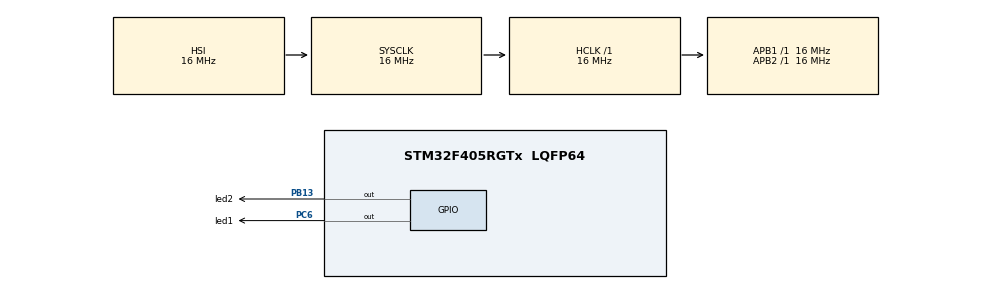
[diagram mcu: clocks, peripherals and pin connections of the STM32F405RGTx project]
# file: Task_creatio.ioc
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Mcu.Family=STM32F4
Mcu.Name=STM32F405RGTx
Mcu.Package=LQFP64
NVIC.PriorityGroup=NVIC_PRIORITYGROUP_4
PB13.GPIO_Label=led2
PB13.Signal=GPIO_Output
PC6.GPIO_Label=led1
PC6.Signal=GPIO_Output
ProjectManager.HeapSize=0x200
ProjectManager.StackSize=0x400
ProjectManager.TargetToolchain=STM32CubeIDE
RCC.AHBFreq_Value=16000000
RCC.APB1Freq_Value=16000000
RCC.APB2Freq_Value=16000000
RCC.CortexFreq_Value=16000000
RCC.HSE_VALUE=25000000
RCC.HSI_VALUE=16000000
RCC.LSE_VALUE=32768
RCC.SYSCLKFreq_VALUE=16000000
RCC.VCOOutputFreq_Value=192000000
board=custom

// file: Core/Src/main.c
/* USER CODE BEGIN Header */
/**
  ******************************************************************************
  * @file           : main.c
  * @brief          : Main program body
  ******************************************************************************
  * @attention
  *
  * Copyright (c) 2025 STMicroelectronics.
  * All rights reserved.
  *
  * This software is licensed under terms that can be found in the LICENSE file
  * in the root directory of this software component.
  * If no LICENSE file comes with this software, it is provided AS-IS.
  *
  ******************************************************************************
  */
/* USER CODE END Header */
#include "main.h"

/* USER CODE BEGIN Includes */
#include "FreeRTOS.h"
#include "task.h"

/* USER CODE END Includes */

void SystemClock_Config(void);
static void MX_GPIO_Init(void);
/* USER CODE BEGIN PFP */
static void myTask1(void *parameter);
static void myTask2(void *parameter);
/* USER CODE END PFP */

int main(void)
{
  /* USER CODE BEGIN 1 */
	TaskHandle_t myTask1Handle;
	TaskHandle_t myTask2Handle;
  /* USER CODE END 1 */

  /* MCU Configuration--------------------------------------------------------*/

  /* Reset of all peripherals, Initializes the Flash interface and the Systick. */
  HAL_Init();

  /* Configure the system clock */
  SystemClock_Config();

  /* Initialize all configured peripherals */
  MX_GPIO_Init();
  /* USER CODE BEGIN 2 */
  xTaskCreate(myTask1, "LED1", 128, NULL, 1, &myTask1Handle);
  xTaskCreate(myTask2, "LED2", 128, NULL, 2, &myTask2Handle);
  vTaskStartScheduler();  // Start FreeRTOS
  /* USER CODE END 2 */

  /* Infinite loop */
  while (1)
  {

  }
}

void SystemClock_Config(void)
{
  RCC_OscInitTypeDef RCC_OscInitStruct = {0};
  RCC_ClkInitTypeDef RCC_ClkInitStruct = {0};

  /** Configure the main internal regulator output voltage
  */
  __HAL_RCC_PWR_CLK_ENABLE();
  __HAL_PWR_VOLTAGESCALING_CONFIG(PWR_REGULATOR_VOLTAGE_SCALE1);

  /** Initializes the RCC Oscillators according to the specified parameters
  * in the RCC_OscInitTypeDef structure.
  */
  RCC_OscInitStruct.OscillatorType = RCC_OSCILLATORTYPE_HSI;
  RCC_OscInitStruct.HSIState = RCC_HSI_ON;
  RCC_OscInitStruct.HSICalibrationValue = RCC_HSICALIBRATION_DEFAULT;
  RCC_OscInitStruct.PLL.PLLState = RCC_PLL_NONE;
  if (HAL_RCC_OscConfig(&RCC_OscInitStruct) != HAL_OK)
  {
    Error_Handler();
  }

  /** Initializes the CPU, AHB and APB buses clocks
  */
  RCC_ClkInitStruct.ClockType = RCC_CLOCKTYPE_HCLK|RCC_CLOCKTYPE_SYSCLK
                              |RCC_CLOCKTYPE_PCLK1|RCC_CLOCKTYPE_PCLK2;
  RCC_ClkInitStruct.SYSCLKSource = RCC_SYSCLKSOURCE_HSI;
  RCC_ClkInitStruct.AHBCLKDivider = RCC_SYSCLK_DIV1;
  RCC_ClkInitStruct.APB1CLKDivider = RCC_HCLK_DIV1;
  RCC_ClkInitStruct.APB2CLKDivider = RCC_HCLK_DIV1;

  if (HAL_RCC_ClockConfig(&RCC_ClkInitStruct, FLASH_LATENCY_0) != HAL_OK)
  {
    Error_Handler();
  }
}

static void MX_GPIO_Init(void)
{
  GPIO_InitTypeDef GPIO_InitStruct = {0};

  /* GPIO Ports Clock Enable */
  __HAL_RCC_GPIOB_CLK_ENABLE();
  __HAL_RCC_GPIOC_CLK_ENABLE();

  /*Configure GPIO pin Output Level */
  HAL_GPIO_WritePin(led2_GPIO_Port, led2_Pin, GPIO_PIN_RESET);

  /*Configure GPIO pin Output Level */
  HAL_GPIO_WritePin(led1_GPIO_Port, led1_Pin, GPIO_PIN_RESET);

  /*Configure GPIO pin : led2_Pin */
  GPIO_InitStruct.Pin = led2_Pin;
  GPIO_InitStruct.Mode = GPIO_MODE_OUTPUT_PP;
  GPIO_InitStruct.Pull = GPIO_NOPULL;
  GPIO_InitStruct.Speed = GPIO_SPEED_FREQ_LOW;
  HAL_GPIO_Init(led2_GPIO_Port, &GPIO_InitStruct);

  /*Configure GPIO pin : led1_Pin */
  GPIO_InitStruct.Pin = led1_Pin;
  GPIO_InitStruct.Mode = GPIO_MODE_OUTPUT_PP;
  GPIO_InitStruct.Pull = GPIO_NOPULL;
  GPIO_InitStruct.Speed = GPIO_SPEED_FREQ_LOW;
  HAL_GPIO_Init(led1_GPIO_Port, &GPIO_InitStruct);

}
//If a high-priority task is sleeping, lower ones run freely.

/* USER CODE BEGIN 4 */
void myTask1(void *P)
{
    while(1)
    {
        HAL_GPIO_TogglePin(led1_GPIO_Port, led1_Pin);
        vTaskDelay(1000); // 1 second delay
    }
}

void myTask2(void *P)
{
    while(1)
    {
        HAL_GPIO_TogglePin(led2_GPIO_Port, led2_Pin);
        vTaskDelay(3000); // 3 seconds delay
    }
}
/* USER CODE END 4 */

void Error_Handler(void)
{
  __disable_irq();
  while (1)
  {
  }
}
